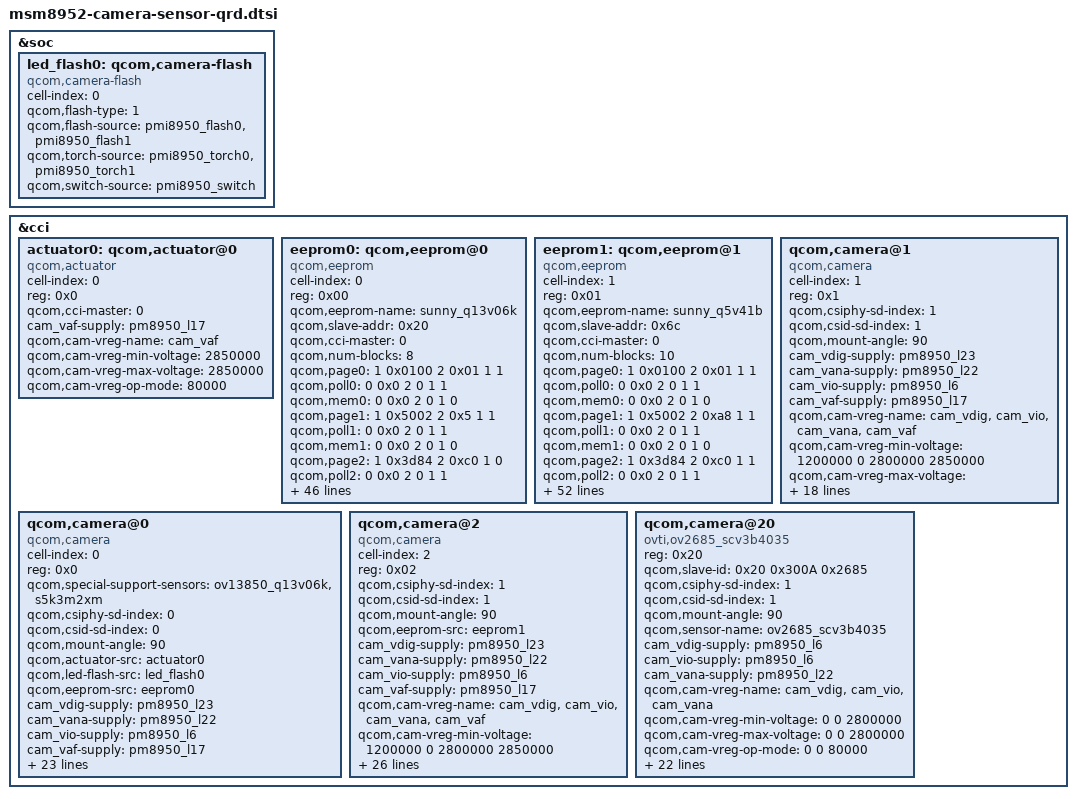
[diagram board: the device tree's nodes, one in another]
/*
 * Copyright (c) 2015, The Linux Foundation. All rights reserved.
 *
 * This program is free software; you can redistribute it and/or modify
 * it under the terms of the GNU General Public License version 2 and
 * only version 2 as published by the Free Software Foundation.
 *
 * This program is distributed in the hope that it will be useful,
 * but WITHOUT ANY WARRANTY; without even the implied warranty of
 * MERCHANTABILITY or FITNESS FOR A PARTICULAR PURPOSE.  See the
 * GNU General Public License for more details.
 */

&soc {
	led_flash0: qcom,camera-flash {
		cell-index = <0>;
		compatible = "qcom,camera-flash";
		qcom,flash-type = <1>;
		qcom,flash-source = <&pmi8950_flash0 &pmi8950_flash1>;
		qcom,torch-source = <&pmi8950_torch0 &pmi8950_torch1>;
		qcom,switch-source = <&pmi8950_switch>;
	};
};

&cci {
	actuator0: qcom,actuator@0 {
		cell-index = <0>;
		reg = <0x0>;
		compatible = "qcom,actuator";
		qcom,cci-master = <0>;
		cam_vaf-supply = <&pm8950_l17>;
		qcom,cam-vreg-name = "cam_vaf";
		qcom,cam-vreg-min-voltage = <2850000>;
		qcom,cam-vreg-max-voltage = <2850000>;
		qcom,cam-vreg-op-mode = <80000>;
	};

	eeprom0: qcom,eeprom@0{
		cell-index = <0>;
		reg = <0x00>;
		qcom,eeprom-name = "sunny_q13v06k";
		compatible = "qcom,eeprom";
		qcom,slave-addr = <0x20>;
		qcom,cci-master = <0>;
		qcom,num-blocks = <8>;

		qcom,page0 = <1 0x0100 2 0x01 1 1>;
		qcom,poll0 = <0 0x0 2 0 1 1>;
		qcom,mem0 = <0 0x0 2 0 1 0>;
		qcom,page1 = <1 0x5002 2 0x5 1 1>;
		qcom,poll1 = <0 0x0 2 0 1 1>;
		qcom,mem1 = <0 0x0 2 0 1 0>;
		qcom,page2 = <1 0x3d84 2 0xc0 1 0>;
		qcom,poll2 = <0 0x0 2 0 1 1>;
		qcom,mem2 = <0 0x0 2 0 1 0>;
		qcom,page3 = <1 0x3d88 2 0x7220 2 0>;
		qcom,poll3 = <0 0x0 2 0 1 1>;
		qcom,mem3 = <0 0x0 2 0 1 0>;
		qcom,page4 = <1 0x3d8a 2 0x73BA 2 0>;
		qcom,poll4 = <0 0x0 2 0 1 1>;
		qcom,mem4 = <0 0x0 2 0 1 0>;
		qcom,page5 = <1 0x3d81 2 0x01 1 15>;
		qcom,poll5 = <0 0x0 2 0 1 1>;
		qcom,mem5 = <411 0x7220 2 0 1 0>;
		qcom,page6 = <1 0x5002 2 0x7 1 1>;
		qcom,poll6 = <0 0x0 2 0 1 1>;
		qcom,mem6 = <0 0x0 2 0 1 0>;
		qcom,page7 = <0 0 0 0 0 0>;
		qcom,poll7 = <0 0 0 0 0 0>;
		qcom,saddr7 = <0xa0>;
		qcom,mem7 = <470 0x16ba 2 0 1 0>;

		cam_vdig-supply = <&pm8950_l23>;
		cam_vana-supply = <&pm8950_l22>;
		cam_vio-supply = <&pm8950_l6>;
		qcom,cam-vreg-name = "cam_vdig", "cam_vio", "cam_vana";
		qcom,cam-vreg-min-voltage = <1200000 0 2800000>;
		qcom,cam-vreg-max-voltage = <1200000 0 2800000>;
		qcom,cam-vreg-op-mode = <200000 0 80000>;
		pinctrl-names = "cam_default", "cam_suspend";
		pinctrl-0 = <&cam_sensor_mclk0_default &cam_sensor_rear_default>;
		pinctrl-1 = <&cam_sensor_mclk0_sleep &cam_sensor_rear_sleep>;
		gpios = <&msm_gpio 26 0>,
			<&msm_gpio 36 0>,
			<&msm_gpio 35 0>;
		qcom,gpio-reset = <1>;
		qcom,gpio-standby = <2>;
		qcom,gpio-req-tbl-num = <0 1 2>;
		qcom,gpio-req-tbl-flags = <1 0 0>;
		qcom,gpio-req-tbl-label = "CAMIF_MCLK0",
			"MCAM_RESET0",
			"MCAM_STANDBY0";

		qcom,cam-power-seq-type = "sensor_vreg",
			"sensor_vreg", "sensor_vreg",
			"sensor_clk",
			"sensor_gpio", "sensor_gpio";
		qcom,cam-power-seq-val = "cam_vio",
			"cam_vana", "cam_vdig",
			"sensor_cam_mclk",
			"sensor_gpio_reset",
			"sensor_gpio_standby";
		qcom,cam-power-seq-cfg-val = <1 1 1 24000000 1 1>;
		qcom,cam-power-seq-delay = <1 1 5 5 5 10>;
		status = "ok";
		clocks = <&clock_gcc clk_mclk0_clk_src>,
				<&clock_gcc clk_gcc_camss_mclk0_clk>;
		clock-names = "cam_src_clk", "cam_clk";
	};

	eeprom1: qcom,eeprom@1{
		cell-index = <1>;
		reg = <0x01>;
		qcom,eeprom-name = "sunny_q5v41b";
		compatible = "qcom,eeprom";
		qcom,slave-addr = <0x6c>;
		qcom,cci-master = <0>;

		qcom,num-blocks = <10>;
		qcom,page0 = <1 0x0100 2 0x01 1 1>;
		qcom,poll0 = <0 0x0 2 0 1 1>;
		qcom,mem0 = <0 0x0 2 0 1 0>;
		qcom,page1 = <1 0x5002 2 0xa8 1 1>;
		qcom,poll1 = <0 0x0 2 0 1 1>;
		qcom,mem1 = <0 0x0 2 0 1 0>;
		qcom,page2 = <1 0x3d84 2 0xc0 1 1>;
		qcom,poll2 = <0 0x0 2 0 1 1>;
		qcom,mem2 = <0 0x0 2 0 1 0>;
		qcom,page3 = <1 0x3d88 2 0x70 1 1>;
		qcom,poll3 = <0 0x0 2 0 1 1>;
		qcom,mem3 = <0 0x3d00 2 0 1 0>;
		qcom,page4 = <1 0x3d89 2 0x10 1 1>;
		qcom,poll4 = <0 0x0 2 0 1 1>;
		qcom,mem4 = <0 0x3d00 2 0 1 0>;
		qcom,page5 = <1 0x3d8a 2 0x70 1 1>;
		qcom,poll5 = <0 0x0 2 0 1 1>;
		qcom,mem5 = <0 0x3d00 2 0 1 0>;
		qcom,page6 = <1 0x3d8b 2 0x29 1 1>;
		qcom,poll6 = <0 0x0 2 0 1 1>;
		qcom,mem6 = <0 0x3d00 2 0 1 0>;
		qcom,page7 = <1 0x3d81 2 0x01 1 5>;
		qcom,poll7 = <0 0x0 2 0 1 1>;
		qcom,mem7 = <26 0x7010 2 0 1 1>;
		qcom,page8 = <1 0x5002 2 0xaa 1 1>;
		qcom,poll8 = <0 0x0 2 0 1 1>;
		qcom,mem8 = <0 0x0 2 0 1 0>;
		qcom,page9 = <1 0x0100 2 0x00 1 1>;
		qcom,poll9 = <0 0x0 2 0 1 1>;
		qcom,mem9 = <0 0x0 2 0 1 0>;

		cam_vdig-supply = <&pm8950_l23>;
		cam_vana-supply = <&pm8950_l22>;
		cam_vio-supply = <&pm8950_l6>;
		qcom,cam-vreg-name = "cam_vdig", "cam_vio", "cam_vana";
		qcom,cam-vreg-type = <0 1 0>;
		qcom,cam-vreg-min-voltage = <1200000 0 2800000>;
		qcom,cam-vreg-max-voltage = <1200000 0 2800000>;
		qcom,cam-vreg-op-mode = <105000 0 80000>;
		pinctrl-names = "cam_default", "cam_suspend";
		pinctrl-0 = <&cam_sensor_mclk2_default &cam_sensor_front1_default>;
		pinctrl-1 = <&cam_sensor_mclk2_sleep &cam_sensor_front1_sleep>;
		gpios = <&msm_gpio 28 0>,
			<&msm_gpio 40 0>,
			<&msm_gpio 39 0>;
		qcom,gpio-reset = <1>;
		qcom,gpio-standby = <2>;
		qcom,gpio-req-tbl-num = <0 1 2>;
		qcom,gpio-req-tbl-flags = <1 0 0>;
		qcom,gpio-req-tbl-label = "CAMIF_MCLK2",
					  "CAM_RESET2",
					  "CAM_STANDBY2";
		qcom,cam-power-seq-type = "sensor_vreg",
			"sensor_vreg", "sensor_vreg",
			"sensor_gpio", "sensor_gpio",
			"sensor_clk";
		qcom,cam-power-seq-val = "cam_vio",
			"cam_vana", "cam_vdig",
			"sensor_gpio_reset",
			"sensor_gpio_standby",
			"sensor_cam_mclk" ;
		qcom,cam-power-seq-cfg-val = <1 1 1 1 1 24000000>;
		qcom,cam-power-seq-delay = <10 10 10 10 10 5>;

		clocks = <&clock_gcc clk_mclk2_clk_src>,
			<&clock_gcc clk_gcc_camss_mclk2_clk>;
		clock-names = "cam_src_clk", "cam_clk";
	};

	qcom,camera@0 {
		cell-index = <0>;
		compatible = "qcom,camera";
		reg = <0x0>;
		qcom,special-support-sensors = "ov13850_q13v06k", "s5k3m2xm";
		qcom,csiphy-sd-index = <0>;
		qcom,csid-sd-index = <0>;
		qcom,mount-angle = <90>;
		qcom,actuator-src = <&actuator0>;
		qcom,led-flash-src = <&led_flash0>;
		qcom,eeprom-src = <&eeprom0>;
		cam_vdig-supply = <&pm8950_l23>;
		cam_vana-supply = <&pm8950_l22>;
		cam_vio-supply = <&pm8950_l6>;
		cam_vaf-supply = <&pm8950_l17>;
		qcom,cam-vreg-name = "cam_vdig", "cam_vio", "cam_vana",
							"cam_vaf";
		qcom,cam-vreg-min-voltage = <1200000 0 2800000 2850000>;
		qcom,cam-vreg-max-voltage = <1200000 0 2800000 2850000>;
		qcom,cam-vreg-op-mode = <200000 0 80000 100000>;
		pinctrl-names = "cam_default", "cam_suspend";
		pinctrl-0 = <&cam_sensor_mclk0_default
				&cam_sensor_rear_default>;
		pinctrl-1 = <&cam_sensor_mclk0_sleep &cam_sensor_rear_sleep>;
		gpios = <&msm_gpio 26 0>,
			<&msm_gpio 36 0>,
			<&msm_gpio 35 0>;
		qcom,gpio-reset = <1>;
		qcom,gpio-standby = <2>;
		qcom,gpio-req-tbl-num = <0 1 2>;
		qcom,gpio-req-tbl-flags = <1 0 0>;
		qcom,gpio-req-tbl-label = "CAMIF_MCLK0",
			"CAM_RESET0",
			"CAM_STANDBY0";
		qcom,sensor-position = <0>;
		qcom,sensor-mode = <0>;
		qcom,cci-master = <0>;
		status = "ok";
		clocks = <&clock_gcc clk_mclk0_clk_src>,
				<&clock_gcc clk_gcc_camss_mclk0_clk>;
		clock-names = "cam_src_clk", "cam_clk";
	};

	qcom,camera@1 {
		cell-index = <1>;
		compatible = "qcom,camera";
		reg = <0x1>;
		qcom,csiphy-sd-index = <1>;
		qcom,csid-sd-index = <1>;
		qcom,mount-angle = <90>;
		cam_vdig-supply = <&pm8950_l23>;
		cam_vana-supply = <&pm8950_l22>;
		cam_vio-supply = <&pm8950_l6>;
		cam_vaf-supply = <&pm8950_l17>;
		qcom,cam-vreg-name = "cam_vdig", "cam_vio", "cam_vana",
							"cam_vaf";
		qcom,cam-vreg-min-voltage = <1200000 0 2800000 2850000>;
		qcom,cam-vreg-max-voltage = <1200000 0 2800000 2850000>;
		qcom,cam-vreg-op-mode = <200000 0 80000 100000>;
		pinctrl-names = "cam_default", "cam_suspend";
		pinctrl-0 = <&cam_sensor_mclk1_default &cam_sensor_front_default>;
		pinctrl-1 = <&cam_sensor_mclk1_sleep &cam_sensor_front_sleep>;
		gpios = <&msm_gpio 27 0>,
			<&msm_gpio 38 0>,
			<&msm_gpio 37 0>;
		qcom,gpio-reset = <1>;
		qcom,gpio-standby = <2>;
		qcom,gpio-req-tbl-num = <0 1 2>;
		qcom,gpio-req-tbl-flags = <1 0 0>;
		qcom,gpio-req-tbl-label = "CAMIF_MCLK1",
			"CAM_RESET1",
			"CAM_STANDBY1";
		qcom,sensor-position = <1>;
		qcom,sensor-mode = <0>;
		qcom,cci-master = <0>;
		status = "ok";
		clocks = <&clock_gcc clk_mclk1_clk_src>,
				<&clock_gcc clk_gcc_camss_mclk1_clk>;
		clock-names = "cam_src_clk", "cam_clk";
	};

	qcom,camera@2 {
		cell-index = <2>;
		compatible = "qcom,camera";
		reg = <0x02>;
		qcom,csiphy-sd-index = <1>;
		qcom,csid-sd-index = <1>;
		qcom,mount-angle = <90>;
		qcom,eeprom-src = <&eeprom1>;
		cam_vdig-supply = <&pm8950_l23>;
		cam_vana-supply = <&pm8950_l22>;
		cam_vio-supply = <&pm8950_l6>;
		cam_vaf-supply = <&pm8950_l17>;
		qcom,cam-vreg-name = "cam_vdig", "cam_vio", "cam_vana", "cam_vaf";
		qcom,cam-vreg-min-voltage = <1200000 0 2800000 2850000>;
		qcom,cam-vreg-max-voltage = <1200000 0 2800000 2850000>;
		qcom,cam-vreg-op-mode = <105000 0 80000 100000>;
		qcom,gpio-no-mux = <0>;
		pinctrl-names = "cam_default", "cam_suspend";
		pinctrl-0 = <&cam_sensor_mclk2_default
								&cam_sensor_front1_default
								&cam_sensor_ext_gpio_default>;
		pinctrl-1 = <&cam_sensor_mclk2_sleep
								&cam_sensor_front1_sleep
								&cam_sensor_ext_gpio_sleep>;
		gpios = <&msm_gpio 28 0>,
			<&msm_gpio 40 0>,
			<&msm_gpio 39 0>,
			<&msm_gpio 130 0>,
			<&msm_gpio 131 0>;
		qcom,gpio-reset = <1>;
		qcom,gpio-standby = <2>;
		qcom,gpio-custom1 = <3>;
		qcom,gpio-custom2 = <4>;
		qcom,gpio-req-tbl-num = <0 1 2 3 4>;
		qcom,gpio-req-tbl-flags = <1 0 0 0 0>;
		qcom,gpio-req-tbl-label = "CAMIF_MCLK2",
					  "CAM_RESET2",
					  "CAM_STANDBY2",
						"CAM_CUSTOM1",
						"CAM_CUSTOM2";
		qcom,sensor-position = <1>;
		qcom,sensor-mode = <0>;
		qcom,cci-master = <0>;
		status = "ok";
		clocks = <&clock_gcc clk_mclk2_clk_src>,
			<&clock_gcc clk_gcc_camss_mclk2_clk>;
		clock-names = "cam_src_clk", "cam_clk";
	};

qcom,camera@20 {
		compatible = "ovti,ov2685_scv3b4035";
		reg = <0x20>;
		qcom,slave-id = <0x20 0x300A 0x2685>;
		qcom,csiphy-sd-index = <1>;
		qcom,csid-sd-index = <1>;
		qcom,mount-angle = <90>;
		qcom,sensor-name = "ov2685_scv3b4035";
		cam_vdig-supply = <&pm8950_l6>;
		cam_vio-supply = <&pm8950_l6>;
		cam_vana-supply = <&pm8950_l22>;
		qcom,cam-vreg-name = "cam_vdig", "cam_vio", "cam_vana";
		qcom,cam-vreg-min-voltage = <0 0 2800000>;
		qcom,cam-vreg-max-voltage = <0 0 2800000>;
		qcom,cam-vreg-op-mode = <0 0 80000>;
		qcom,gpio-no-mux = <0>;
		pinctrl-names = "cam_default", "cam_suspend";
		pinctrl-0 = <&cam_sensor_mclk1_default &cam_sensor_front_default>;
		pinctrl-1 = <&cam_sensor_mclk1_sleep &cam_sensor_front_sleep>;
		gpios = <&msm_gpio 27 0>,
			<&msm_gpio 38 0>,
			<&msm_gpio 37 0>;
		qcom,gpio-reset = <1>;
		qcom,gpio-standby = <2>;
		qcom,gpio-req-tbl-num = <0 1 2>;
		qcom,gpio-req-tbl-flags = <1 0 0>;
		qcom,gpio-req-tbl-label = "CAMIF_MCLK1",
			"CAM_RESET1",
			"CAM_STANDBY1";
		qcom,gpio-set-tbl-num = <1 1>;
		qcom,gpio-set-tbl-flags = <0 2>;
		qcom,gpio-set-tbl-delay = <1000 30000>;
		qcom,csi-lane-assign = <0x0004>;
		qcom,csi-lane-mask = <0x18>;
		qcom,sensor-position = <0x100>;
		qcom,sensor-mode = <1>;
		qcom,cci-master = <1>;
		clocks = <&clock_gcc clk_mclk1_clk_src>,
			<&clock_gcc clk_gcc_camss_mclk1_clk>;
		clock-names = "cam_src_clk", "cam_clk";
	};
};
